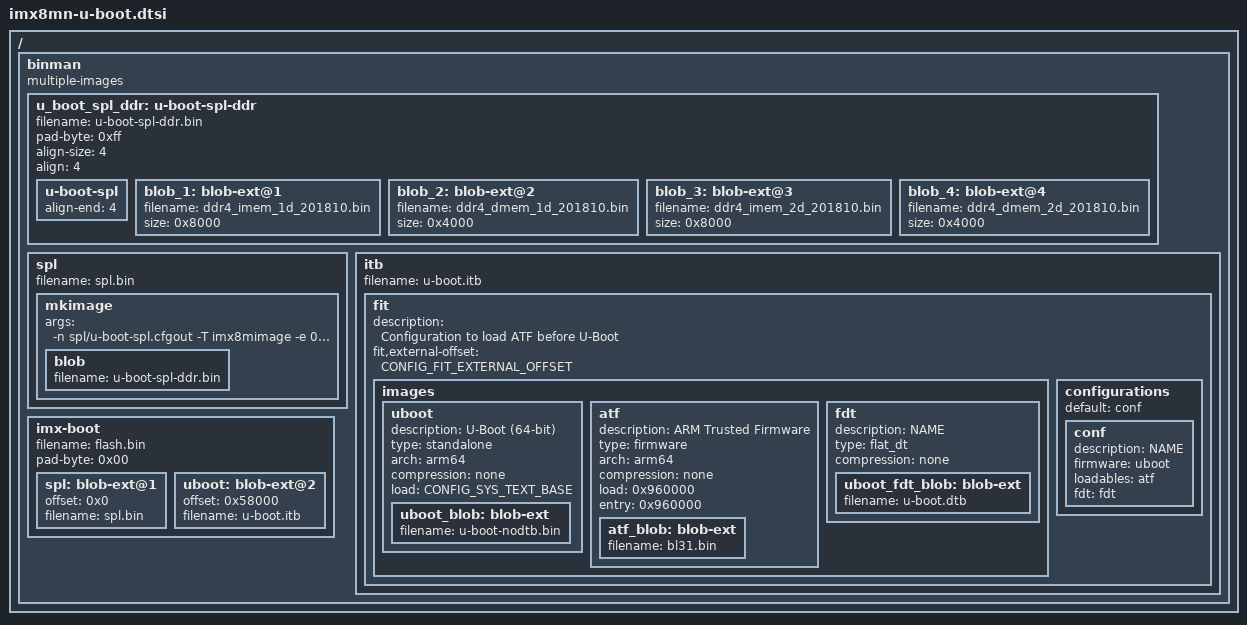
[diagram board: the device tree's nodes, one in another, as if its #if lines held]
// SPDX-License-Identifier: GPL-2.0+
/*
 * Copyright 2019 NXP
 */

/ {
	binman: binman {
		multiple-images;
	};
};

&binman {
	 u_boot_spl_ddr: u-boot-spl-ddr {
		filename = "u-boot-spl-ddr.bin";
		pad-byte = <0xff>;
		align-size = <4>;
		align = <4>;

		u-boot-spl {
			align-end = <4>;
		};
	};

	spl {
		filename = "spl.bin";

		mkimage {
			args = "-n spl/u-boot-spl.cfgout -T imx8mimage -e 0x912000";

			blob {
				filename = "u-boot-spl-ddr.bin";
			};
		};
	};

	itb {
		filename = "u-boot.itb";

		fit {
			description = "Configuration to load ATF before U-Boot";
			#address-cells = <1>;
			fit,external-offset = <CONFIG_FIT_EXTERNAL_OFFSET>;

			images {
				uboot {
					description = "U-Boot (64-bit)";
					type = "standalone";
					arch = "arm64";
					compression = "none";
					load = <CONFIG_SYS_TEXT_BASE>;

					uboot_blob: blob-ext {
						filename = "u-boot-nodtb.bin";
					};
				};

				atf {
					description = "ARM Trusted Firmware";
					type = "firmware";
					arch = "arm64";
					compression = "none";
					load = <0x960000>;
					entry = <0x960000>;

					atf_blob: blob-ext {
						filename = "bl31.bin";
					};
				};

				fdt {
					description = "NAME";
					type = "flat_dt";
					compression = "none";

					uboot_fdt_blob: blob-ext {
						filename = "u-boot.dtb";
					};
				};
			};

			configurations {
				default = "conf";

				conf {
					description = "NAME";
					firmware = "uboot";
					loadables = "atf";
					fdt = "fdt";
				};
			};
		};
	};

	imx-boot {
		filename = "flash.bin";
		pad-byte = <0x00>;

		spl: blob-ext@1 {
			offset = <0x0>;
			filename = "spl.bin";
		};

		uboot: blob-ext@2 {
			offset = <0x58000>;
			filename = "u-boot.itb";
		};
	};
};

#ifdef CONFIG_IMX8M_DDR4
&u_boot_spl_ddr {
	blob_1: blob-ext@1 {
		filename = "ddr4_imem_1d_201810.bin";
		size = <0x8000>;
	};

	blob_2: blob-ext@2 {
		filename = "ddr4_dmem_1d_201810.bin";
		size = <0x4000>;
	};

	blob_3: blob-ext@3 {
		filename = "ddr4_imem_2d_201810.bin";
		size = <0x8000>;
	};

	blob_4: blob-ext@4 {
		filename = "ddr4_dmem_2d_201810.bin";
		size = <0x4000>;
	};
};
#elif CONFIG_IMX8M_LPDDR4
&u_boot_spl_ddr {
	blob_1: blob-ext@1 {
		filename = "lpddr4_pmu_train_1d_imem.bin";
		size = <0x8000>;
	};

	blob_2: blob-ext@2 {
		filename = "lpddr4_pmu_train_1d_dmem.bin";
		size = <0x4000>;
	};

	blob_3: blob-ext@3 {
		filename = "lpddr4_pmu_train_2d_imem.bin";
		size = <0x8000>;
	};

	blob_4: blob-ext@4 {
		filename = "lpddr4_pmu_train_2d_dmem.bin";
		size = <0x4000>;
	};
};
#elif CONFIG_IMX8M_DDR3L
&u_boot_spl_ddr {
	blob_1: blob-ext@1 {
		filename = "ddr3_imem_1d.bin";
		size = <0x8000>;
	};

	blob_2: blob-ext@2 {
		filename = "ddr3_dmem_1d.bin";
		size = <0x4000>;
	};
};
#else
	#error "no valid ddr config selected"
#endif
